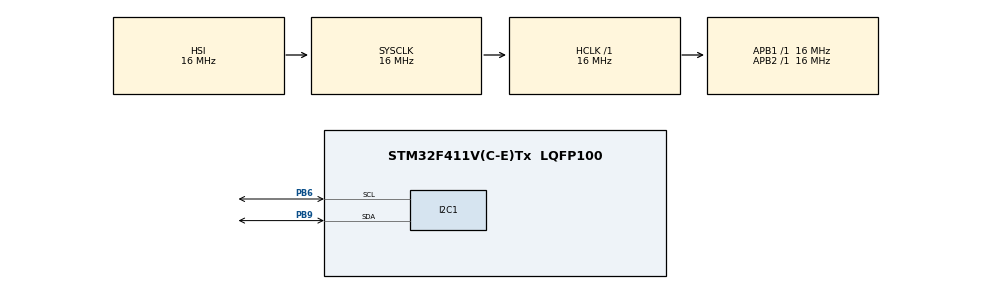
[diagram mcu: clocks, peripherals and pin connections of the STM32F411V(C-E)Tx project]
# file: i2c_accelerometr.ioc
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I2C1.I2C_Mode=I2C_Fast
Mcu.Family=STM32F4
Mcu.Name=STM32F411V(C-E)Tx
Mcu.Package=LQFP100
NVIC.I2C1_ER_IRQn=true\:0\:0\:false\:false\:true
NVIC.I2C1_EV_IRQn=true\:0\:0\:false\:false\:true
NVIC.PriorityGroup=NVIC_PRIORITYGROUP_4
PB6.Mode=I2C
PB6.Signal=I2C1_SCL
PB9.Mode=I2C
PB9.Signal=I2C1_SDA
ProjectManager.HeapSize=0x200
ProjectManager.StackSize=0x400
ProjectManager.TargetToolchain=SW4STM32
RCC.AHBFreq_Value=16000000
RCC.APB1Freq_Value=16000000
RCC.APB2Freq_Value=16000000
RCC.CortexFreq_Value=16000000
RCC.HSE_VALUE=25000000
RCC.HSI_VALUE=16000000
RCC.LSE_VALUE=32768
RCC.SYSCLKFreq_VALUE=16000000
RCC.VCOOutputFreq_Value=192000000
board=i2c_accelerometr

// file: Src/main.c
/**
  ******************************************************************************
  * File Name          : main.c
  * Description        : Main program body
  ******************************************************************************
  *
  * COPYRIGHT(c) 2016 STMicroelectronics
  *
  * Redistribution and use in source and binary forms, with or without modification,
  * are permitted provided that the following conditions are met:
  *   1. Redistributions of source code must retain the above copyright notice,
  *      this list of conditions and the following disclaimer.
  *   2. Redistributions in binary form must reproduce the above copyright notice,
  *      this list of conditions and the following disclaimer in the documentation
  *      and/or other materials provided with the distribution.
  *   3. Neither the name of STMicroelectronics nor the names of its contributors
  *      may be used to endorse or promote products derived from this software
  *      without specific prior written permission.
  *
  * THIS SOFTWARE IS PROVIDED BY THE COPYRIGHT HOLDERS AND CONTRIBUTORS "AS IS"
  * AND ANY EXPRESS OR IMPLIED WARRANTIES, INCLUDING, BUT NOT LIMITED TO, THE
  * IMPLIED WARRANTIES OF MERCHANTABILITY AND FITNESS FOR A PARTICULAR PURPOSE ARE
  * DISCLAIMED. IN NO EVENT SHALL THE COPYRIGHT HOLDER OR CONTRIBUTORS BE LIABLE
  * FOR ANY DIRECT, INDIRECT, INCIDENTAL, SPECIAL, EXEMPLARY, OR CONSEQUENTIAL
  * DAMAGES (INCLUDING, BUT NOT LIMITED TO, PROCUREMENT OF SUBSTITUTE GOODS OR
  * SERVICES; LOSS OF USE, DATA, OR PROFITS; OR BUSINESS INTERRUPTION) HOWEVER
  * CAUSED AND ON ANY THEORY OF LIABILITY, WHETHER IN CONTRACT, STRICT LIABILITY,
  * OR TORT (INCLUDING NEGLIGENCE OR OTHERWISE) ARISING IN ANY WAY OUT OF THE USE
  * OF THIS SOFTWARE, EVEN IF ADVISED OF THE POSSIBILITY OF SUCH DAMAGE.
  *
  ******************************************************************************
  */
#include "main.h"
#include "stm32f4xx_hal.h"

I2C_HandleTypeDef hi2c1;
static uint16_t z_data=0;

/* USER CODE BEGIN PV */
/* Private variables ---------------------------------------------------------*/
#define ACC_ADDRESS (0x19 << 1) // adres akcelerometru: 0011 001x
#define CTRL_REG1_A_ADDRESS 0x20 //adres rejstru CTRL_REG1_A w którym ustwaia się trzyb pracy akcelerometru
#define OUT_Z_H_A 0x2d //register with high byte of z axe information
uint8_t ACC_REG1_A_VALUE=0x54;//0101 - 100Hz speed, 0100 - normal power, z axe enable only
/* USER CODE END PV */

void SystemClock_Config(void);
void Error_Handler(void);
static void MX_GPIO_Init(void);
static void MX_I2C1_Init(void);

/* USER CODE BEGIN PFP */
/* Private function prototypes -----------------------------------------------*/

/* USER CODE END PFP */

int main(void)
{

  /* MCU Configuration----------------------------------------------------------*/

  /* Reset of all peripherals, Initializes the Flash interface and the Systick. */
  HAL_Init();

  /* Configure the system clock */
  SystemClock_Config();

  /* Initialize all configured peripherals */
  MX_GPIO_Init();
  MX_I2C1_Init();

  /* USER CODE BEGIN 2 */
  HAL_I2C_Mem_Write(&hi2c1, ACC_ADDRESS, CTRL_REG1_A_ADDRESS, 1, &ACC_REG1_A_VALUE, 1, 100);

  /* USER CODE END 2 */

  /* Infinite loop */
  while (1)
  {

  /* USER CODE BEGIN 3 */
	uint8_t raw_z_data[2];
	HAL_I2C_Mem_Read(&hi2c1, ACC_ADDRESS, OUT_Z_H_A, 1, &raw_z_data, 2, 100);
	z_data=((raw_z_data[0]<<8)|raw_z_data[1]);
  /* USER CODE END 3 */
  }

}

/** System Clock Configuration
*/
void SystemClock_Config(void)
{

  RCC_OscInitTypeDef RCC_OscInitStruct;
  RCC_ClkInitTypeDef RCC_ClkInitStruct;

    /**Configure the main internal regulator output voltage
    */
  __HAL_RCC_PWR_CLK_ENABLE();

  __HAL_PWR_VOLTAGESCALING_CONFIG(PWR_REGULATOR_VOLTAGE_SCALE1);

    /**Initializes the CPU, AHB and APB busses clocks
    */
  RCC_OscInitStruct.OscillatorType = RCC_OSCILLATORTYPE_HSI;
  RCC_OscInitStruct.HSIState = RCC_HSI_ON;
  RCC_OscInitStruct.HSICalibrationValue = 16;
  RCC_OscInitStruct.PLL.PLLState = RCC_PLL_NONE;
  if (HAL_RCC_OscConfig(&RCC_OscInitStruct) != HAL_OK)
  {
    Error_Handler();
  }

    /**Initializes the CPU, AHB and APB busses clocks
    */
  RCC_ClkInitStruct.ClockType = RCC_CLOCKTYPE_HCLK|RCC_CLOCKTYPE_SYSCLK
                              |RCC_CLOCKTYPE_PCLK1|RCC_CLOCKTYPE_PCLK2;
  RCC_ClkInitStruct.SYSCLKSource = RCC_SYSCLKSOURCE_HSI;
  RCC_ClkInitStruct.AHBCLKDivider = RCC_SYSCLK_DIV1;
  RCC_ClkInitStruct.APB1CLKDivider = RCC_HCLK_DIV1;
  RCC_ClkInitStruct.APB2CLKDivider = RCC_HCLK_DIV1;

  if (HAL_RCC_ClockConfig(&RCC_ClkInitStruct, FLASH_LATENCY_0) != HAL_OK)
  {
    Error_Handler();
  }

    /**Configure the Systick interrupt time
    */
  HAL_SYSTICK_Config(HAL_RCC_GetHCLKFreq()/1000);

    /**Configure the Systick
    */
  HAL_SYSTICK_CLKSourceConfig(SYSTICK_CLKSOURCE_HCLK);

  /* SysTick_IRQn interrupt configuration */
  HAL_NVIC_SetPriority(SysTick_IRQn, 0, 0);
}

/* I2C1 init function */
static void MX_I2C1_Init(void)
{

  hi2c1.Instance = I2C1;
  hi2c1.Init.ClockSpeed = 400000;
  hi2c1.Init.DutyCycle = I2C_DUTYCYCLE_2;
  hi2c1.Init.OwnAddress1 = 0;
  hi2c1.Init.AddressingMode = I2C_ADDRESSINGMODE_7BIT;
  hi2c1.Init.DualAddressMode = I2C_DUALADDRESS_DISABLE;
  hi2c1.Init.OwnAddress2 = 0;
  hi2c1.Init.GeneralCallMode = I2C_GENERALCALL_DISABLE;
  hi2c1.Init.NoStretchMode = I2C_NOSTRETCH_DISABLE;
  if (HAL_I2C_Init(&hi2c1) != HAL_OK)
  {
    Error_Handler();
  }

}

/** Pinout Configuration
*/
static void MX_GPIO_Init(void)
{

  /* GPIO Ports Clock Enable */
  __HAL_RCC_GPIOB_CLK_ENABLE();

}

void Error_Handler(void)
{
  while(1)
  {
  }
}

/************************ (C) COPYRIGHT STMicroelectronics *****END OF FILE****/
